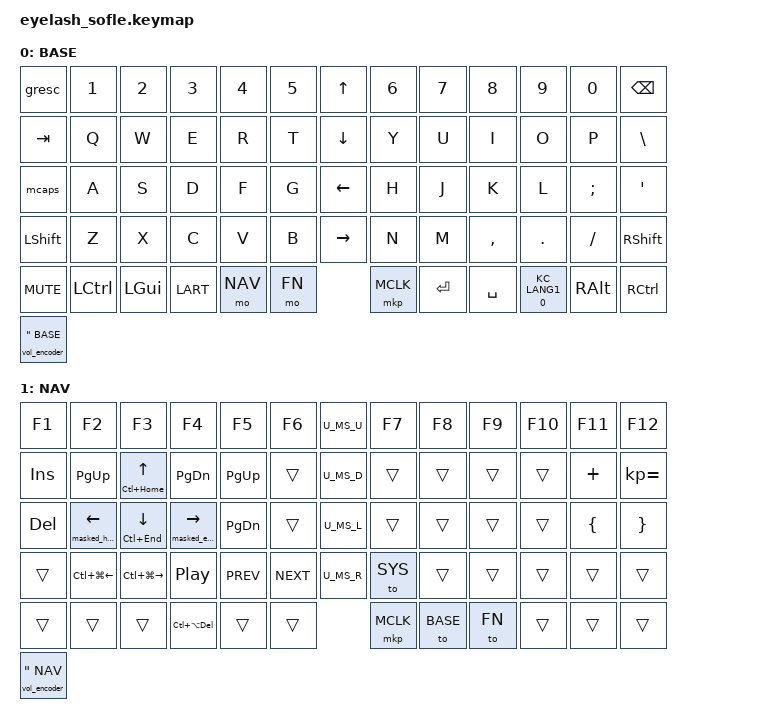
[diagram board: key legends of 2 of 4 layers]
/ {
#include <input/processors.dtsi>
#include <zephyr/dt-bindings/input/input-event-codes.h>
#include <behaviors.dtsi>
#include <dt-bindings/zmk/bt.h>
#include <dt-bindings/zmk/ext_power.h>
#include <dt-bindings/zmk/keys.h>
#include <dt-bindings/zmk/pointing.h>
#include <dt-bindings/zmk/outputs.h>
#include <dt-bindings/zmk/rgb.h>

#include "zmk-helpers/helper.h"
#include "zmk-helpers/key-labels/sofle_eyelash_3c.h"


/* ──────────────────────────────────────────────────────────────── */
/*                        Constants & Defaults                      */
/* ──────────────────────────────────────────────────────────────── */

#define COMBO_TERM_FAST 18
#define COMBO_TERM_SLOW 30

#define COMBO_IDLE_FAST 150
#define COMBO_IDLE_SLOW 50

#define XXX &none
#define ___ &trans

#define QUICK_TAP_MS 175

#define BASE 0
#define NAV 1
#define FN 2
#define SYS 3

#define DLEFT  &kp LC(LG(LEFT_ARROW))
#define DRIGHT &kp LC(LG(RIGHT_ARROW))
#define HYPER &kp LC(LA(LG(LSHFT)))

#define KEYS_L LT0 LT1 LT2 LT3 LT4 LM0 LM1 LM2 LM3 LM4 LB0 LB1 LB2 LB3 LB4  // Left-hand keys
#define KEYS_R RT0 RT1 RT2 RT3 RT4 RM0 RM1 RM2 RM3 RM4 RB0 RB1 RB2 RB3 RB4  // Right-hand keys
#define THUMBS LH4 LH3 LH2 LH1 LH0 RH0 RH1 RH2 RH3 RH4                      // Thumb keys

/* ──────────────────────────────────────────────────────────────── */
/*                     Home Row Mods (Timeless HRMs)                */
/* ──────────────────────────────────────────────────────────────── */

#define MAKE_HRM(NAME, HOLD, TAP, TRIGGER_POS)                                 \
  ZMK_HOLD_TAP(NAME, bindings = <HOLD>, <TAP>; flavor = "balanced";            \
               tapping-term-ms = <280>; quick-tap-ms = <QUICK_TAP_MS>;         \
               require-prior-idle-ms = <150>; hold-trigger-on-release;         \
               hold-trigger-key-positions = <TRIGGER_POS>;)

MAKE_HRM(hml, &kp, &kp, KEYS_R THUMBS) // Left-hand HRMs
MAKE_HRM(hmr, &kp, &kp, KEYS_L THUMBS) // Right-hand HRMs


/* ──────────────────────────────────────────────────────────────── */
/*                         Encoder behaviors                        */
/* ──────────────────────────────────────────────────────────────── */

/ {
  rgb_encoder: rgb_encoder {
      compatible = "zmk,behavior-sensor-rotate";
      #sensor-binding-cells = <0>;
      bindings = <&rgb_ug RGB_BRI>, <&rgb_ug RGB_BRD>;
      tap-ms = <20>;
  };

  vol_encoder: vol_encoder {
      compatible = "zmk,behavior-sensor-rotate";
      #sensor-binding-cells = <0>;
      bindings = <&kp C_VOL_UP>, <&kp C_VOL_DN>;
      tap-ms = <20>;
  };
};


/* ──────────────────────────────────────────────────────────────── */
/*                            Nav cluster                           */
/* ──────────────────────────────────────────────────────────────── */

#define MT_CORE                                                                \
  flavor = "tap-preferred";                                                    \
  tapping-term-ms = <220>;                                                     \
  quick-tap-ms = <220>;                                                        \
  hold-trigger-key-positions = <0>;

&mt { MT_CORE };

// Modifier-morphing wrapper to mask accidental cursor jumps
#define MASK_MODS(NAME, MODS, BINDING)                                         \
  ZMK_MOD_MORPH(NAME, bindings = <BINDING>, <BINDING>; mods = <MODS>;)

MASK_MODS(masked_home, (MOD_LCTL), &kp HOME)
MASK_MODS(masked_end,  (MOD_LCTL), &kp END)

ZMK_HOLD_TAP(mt_home, bindings = <&masked_home>, <&kp>; MT_CORE)
ZMK_HOLD_TAP(mt_end, bindings = <&masked_end>, <&kp>; MT_CORE)

// 새로운 ZMK_HOLD_TAP 비헤이비어 정의
// 짧게 누르면 한영 전환 (KC_LANG1), 길게 누르면 KC_APP
ZMK_HOLD_TAP(han_eng_app_ht,
  bindings = <&kp KC_APP>,    // 홀드 액션: KC_APP (어플리케이션/컨텍스트 메뉴 키)
             <&kp>;           // 탭 액션: &kp 매크로에 키 코드를 전달할 준비
  MT_CORE                     // MT_CORE에서 정의된 공통 탭/홀드 속성 사용
)

#define NAV_LEFT  &mt_home 0   LEFT  // Tap: left  | Long-tap: start of line.
#define NAV_RIGHT &mt_end 0    RIGHT // Tap: right | Long-tap: end   of line.
#define NAV_UP    &mt LC(HOME) UP    // Tap: up    | Long-tap: start of doc.
#define NAV_DOWN  &mt LC(END)  DOWN  // Tap: down  | Long-tap: end   of doc.

// 이제 키맵에 이 비헤이비어를 할당할 수 있는 매크로를 정의
// '#define' 문을 사용하여 키맵 레이어에 쉽게 사용할 수 있도록 합니다.
// (여기서는 KC_LANG1을 한영 전환 키로 사용합니다. 시스템에 따라 KC_RALT를 사용할 수도 있습니다.)
#define HAN_ENG_APP_KEY &han_eng_app_ht 0 KC_LANG1 // 짧게: 한영 전환 | 길게: KC_APP

// 만약 KC_RALT를 한영 전환 키로 선호한다면:
// #define HAN_ENG_APP_KEY_RALT &han_eng_app_ht 0 KC_RALT // 짧게: 한영 전환 (오른쪽 Alt) | 길게: KC_APP


/* ──────────────────────────────────────────────────────────────── */
/*                              Combos                              */
/* ──────────────────────────────────────────────────────────────── */

ZMK_COMBO(selectall, &kp LC(A), LB4 LB3, BASE, COMBO_TERM_FAST, COMBO_IDLE_FAST)
ZMK_COMBO(copy,      &kp LC(C), LB3 LB2, BASE, COMBO_TERM_FAST, COMBO_IDLE_FAST)
ZMK_COMBO(paste,     &kp LC(V), LB2 LB1, BASE, COMBO_TERM_FAST, COMBO_IDLE_FAST)

ZMK_COMBO(lbkt, &kp LBKT, RB1 RB2, BASE, COMBO_TERM_FAST, COMBO_IDLE_FAST)
ZMK_COMBO(rbkt, &kp RBKT, RB2 RB3, BASE, COMBO_TERM_FAST, COMBO_IDLE_FAST)

// 새로운 콤보: Layer 1 키와 Layer 2 키를 함께 눌러 Layer 3으로 이동
ZMK_COMBO(layer1_2_to_layer3,
          &to SYS, // 콤보 성공 시 SYS로 즉시 이동
          <LH1 LH0>, // 여기에 실제 "레이어 1 키"와 "레이어 2 키"의 위치(인덱스)를 입력
                           // 예: <10 15> (만약 P1_POS가 10, P2_POS가 15라면)
                           // 또는, 만약 LB1, LB2 등과 같은 매크로로 정의되어 있다면:
                           // <LB_LAYER1_KEY LB_LAYER2_KEY>
          BASE, // BASE 레이어에서 이 콤보가 작동하도록 허용 (필요에 따라 다른 레이어 추가 가능)
          COMBO_TERM_FAST, // 빠르게 눌렀다 떼야 작동
          COMBO_IDLE_FAST  // 콤보 키를 누른 상태에서 다른 키를 누르면 콤보 취소될 수 있음
)

/* ──────────────────────────────────────────────────────────────── */
/*                            Behaviors                             */
/* ──────────────────────────────────────────────────────────────── */

ZMK_BEHAVIOR(mcaps, macro,
  tap-ms = <200>;
  bindings = <&kp CAPS>;
)


/* ──────────────────────────────────────────────────────────────── */
/*                           Mouse bindings                         */
/* ──────────────────────────────────────────────────────────────── */

#include "mouse.dtsi"


/*                             63 KEY MATRIX / LAYOUT MAPPING
Based on the pre-built Sofle split keyboards from AliExpress, seller 3C, Nice!View edition
https://github.com/a741725193/zmk-sofle

  ╭────────────────────────────╮                             ╭────────────────────────────╮
  │  0   1   2   3   4   5     │               ╭────╮        │      7   8   9  10  11  12 │
  │ 13  14  15  16  17  18     │           ╭───╯  6 ╰───╮    │     20  21  22  23  24  25 │
  │ 26  27  28  29  30  31     │  ╭────╮   │ 32  58  45 │    │     33  34  35  36  37  38 │
  │ 39  40  41  42  43  44     │  │ 52 │   ╰───╮ 19 ╭───╯    │     46  47  48  49  50  51 │
  ╰───────╮ 53  54  55  56  57 │  ╰────╯       ╰────╯        │ 59  60  61  62  63 ╭───────╯
          ╰────────────────────╯                             ╰────────────────────╯
  ╭─────────────────────────────╮                            ╭─────────────────────────────╮          
  │ LN5 LN4 LN3 LN2 LN1 LN0     │              ╭─────╮       │     RN0 RN1 RN2 RN3 RN4 RN5 │
  │ LT5 LT4 LT3 LT2 LT1 LT0     │          ╭───╯ JS0 ╰───╮   │     RT0 RT1 RT2 RT3 RT4 RT5 │
  │ LM5 LM4 LM3 LM2 LM1 LM0     │ ╭─────╮  │ JS1 JS2 JS3 │   │     RM0 RM1 RM2 RM3 RM4 RM5 │
  │ LB5 LB4 LB3 LB2 LB1 LB0     │ │ LEC │  ╰───╮ JS4 ╭───╯   │     RB0 RB1 RB2 RB3 RB4 RB5 │
  ╰───────╮ LH4 LH3 LH2 LH1 LH0 │ ╰─────╯      ╰─────╯       │ RH0 RH1 RH2 RH3 RH4 ╭───────╯
          ╰─────────────────────╯                            ╰─────────────────────╯         */

ZMK_LAYER(BASE,
  //                                                                                                             HAT CONTROLS
  // ╭─────────────┬─────────────┬─────────────┬─────────────┬─────────────┬─────────────╮                      ╭─────────────────╮  ╭─────────────┬─────────────┬─────────────┬─────────────┬─────────────┬─────────────╮
      &gresc        &kp N1        &kp N2        &kp N3        &kp N4        &kp N5                                &kp UP_ARROW        &kp N6        &kp N7        &kp N8        &kp N9        &kp N0        &kp BACKSPACE 
  // ├─────────────┼─────────────┼─────────────┼─────────────┼─────────────┼─────────────┤                      ├─────────────────┤  ├─────────────┼─────────────┼─────────────┼─────────────┼─────────────┼─────────────┤
      &kp TAB       &kp Q         &kp W         &kp E         &kp R         &kp T                                 &kp DOWN_ARROW      &kp Y         &kp U         &kp I         &kp O         &kp P         &kp BACKSLASH        
  // ├─────────────┼─────────────┼─────────────┼─────────────┼─────────────┼─────────────┤                      ├─────────────────┤  ├─────────────┼─────────────┼─────────────┼─────────────┼─────────────┼─────────────┤
      &mcaps        &kp A         &kp S         &kp D         &kp F         &kp G                                 &kp LEFT_ARROW      &kp H         &kp J         &kp K         &kp L         &kp SEMI      &kp APOS        
  // ├─────────────┼─────────────┼─────────────┼─────────────┼─────────────┼─────────────┤                      ├─────────────────┤  ├─────────────┼─────────────┼─────────────┼─────────────┼─────────────┼─────────────┤
      &kp LSHIFT    &kp Z         &kp X         &kp C         &kp V         &kp B                                 &kp RIGHT_ARROW     &kp N         &kp M         &kp COMMA     &kp PERIOD    &kp SLASH     &kp RSHIFT
  // ╰┬──────────┬─┴─────────────┼─────────────┼─────────────┼─────────────┼─────────────┼─────────────╮   ╭────┴─────╮╭──────────┴──┴─────────────┼─────────────┼─────────────┼─────────────┼─────────────┼─────────────┼
       &kp C_MUTE                 &kp LCTRL     &kp LGUI      &kp LART     &mo NAV       &mo FN            &mkp MCLK   &kp ENTER     &kp SPACE     HAN_ENG_APP_KEY &kp RALT     &kp RCTRL
  //  ╰──────────╯               ╰─────────────┴─────────────┴─────────────┴─────────────┴─────────────╯   ╰──────────╯╰─────────────┴─────────────┴─────────────┴─────────────┴─────────────╯
  //  ENCODER PRESS                                                                                         HAT PRESS
, &vol_encoder, "BASE")

ZMK_LAYER(NAV,
  //                                                                                                             HAT CONTROLS
  // ╭─────────────┬─────────────┬─────────────┬─────────────┬─────────────┬─────────────╮                      ╭─────────────────╮  ╭─────────────┬─────────────┬─────────────┬─────────────┬─────────────┬─────────────╮
      &kp F1        &kp F2        &kp F3        &kp F4        &kp F5        &kp F6                               U_MS_U               &kp F7        &kp F8        &kp F9        &kp F10       &kp F11       &kp F12 
  // ├─────────────┼─────────────┼─────────────┼─────────────┼─────────────┼─────────────┤                      ├─────────────────┤  ├─────────────┼─────────────┼─────────────┼─────────────┼─────────────┼─────────────┤
      &kp INSERT    &kp PG_UP     NAV_UP        &kp PG_DN     &kp PG_UP     ___                                  U_MS_D               ___           ___           ___           ___           &kp PLUS      &kp KP_EQUAL        
  // ├─────────────┼─────────────┼─────────────┼─────────────┼─────────────┼─────────────┤                      ├─────────────────┤  ├─────────────┼─────────────┼─────────────┼─────────────┼─────────────┼─────────────┤
      &kp DEL       NAV_LEFT      NAV_DOWN      NAV_RIGHT     &kp PG_DN     ___                                  U_MS_L               ___           ___           ___           ___           &kp LBRC      &kp RBRC         
  // ├─────────────┼─────────────┼─────────────┼─────────────┼─────────────┼─────────────┤                      ├─────────────────┤  ├─────────────┼─────────────┼─────────────┼─────────────┼─────────────┼─────────────┤
      ___           DLEFT         DRIGHT        &kp C_PP      &kp C_PREV    &kp C_NEXT                           U_MS_R               &to SYS       ___           ___           ___           ___           ___ 
  // ╰┬──────────┬─┴─────────────┼─────────────┼─────────────┼─────────────┼─────────────┼─────────────╮   ╭────┴─────╮╭──────────┴──┴─────────────┼─────────────┼─────────────┼─────────────┼─────────────┼─────────────┼
       ___                        ___           ___           &kp LC(LA(DEL)) ___         ___               &mkp MCLK   &to BASE      &to FN        ___           ___           ___
  //  ╰──────────╯               ╰─────────────┴─────────────┴─────────────┴─────────────┴─────────────╯   ╰──────────╯╰─────────────┴─────────────┴─────────────┴─────────────┴─────────────╯
  //  ENCODER PRESS                                                                                         HAT PRESS
, &vol_encoder, "NAV")

ZMK_LAYER(FN,
  //                                                                                                             HAT CONTROLS
  // ╭─────────────┬─────────────┬─────────────┬─────────────┬─────────────┬─────────────╮                      ╭─────────────────╮  ╭─────────────┬─────────────┬─────────────┬─────────────┬─────────────┬─────────────╮
      ___           &kp F1        &kp F2        &kp F3        &kp F4        &kp F5                               U_MS_U               ___           &kp NUM       &kp PSLS      &kp PASTE     &kp PMNS      ___ 
  // ├─────────────┼─────────────┼─────────────┼─────────────┼─────────────┼─────────────┤                      ├─────────────────┤  ├─────────────┼─────────────┼─────────────┼─────────────┼─────────────┼─────────────┤
      ___           &kp PG_UP     NAV_UP        &kp PG_DN     &kp PG_UP     ___                                  U_MS_D               ___           &kp P7        &kp P8        &kp P9        &kp PPLS        
  // ├─────────────┼─────────────┼─────────────┼─────────────┼─────────────┼─────────────┤                      ├─────────────────┤  ├─────────────┼─────────────┼─────────────┼─────────────┼─────────────┼─────────────┤
      ___           NAV_LEFT      NAV_DOWN      NAV_RIGHT     &kp PG_DN     ___                                  U_MS_L               ___           &kp P4        &kp P5        &kp P6        ___           ___         
  // ├─────────────┼─────────────┼─────────────┼─────────────┼─────────────┼─────────────┤                      ├─────────────────┤  ├─────────────┼─────────────┼─────────────┼─────────────┼─────────────┼─────────────┤
      ___           ___           ___           ___           ___           ___                                  U_MS_R               &to SYS       &kp P1        &kp P2        &kp P3        &kp PENT      ___ 
  // ╰┬──────────┬─┴─────────────┼─────────────┼─────────────┼─────────────┼─────────────┼─────────────╮   ╭────┴─────╮╭──────────┴──┴─────────────┼─────────────┼─────────────┼─────────────┼─────────────┼─────────────┼
       ___                        ___           ___           ___           ___           ___               &mkp MCLK   &to BASE      &to NAV       &kp P0        &kp P0        &kp PDOT
  //  ╰──────────╯               ╰─────────────┴─────────────┴─────────────┴─────────────┴─────────────╯   ╰──────────╯╰─────────────┴─────────────┴─────────────┴─────────────┴─────────────╯
  //  ENCODER PRESS                                                                                         HAT PRESS
, &vol_encoder, "FN")

ZMK_LAYER(SYS,
  //                                                                                                             HAT CONTROLS
  // ╭─────────────┬─────────────┬─────────────┬─────────────┬─────────────┬─────────────╮                      ╭─────────────────╮  ╭─────────────┬─────────────┬─────────────┬─────────────┬─────────────┬─────────────╮
      ___           &bt BT_SEL 0  &bt BT_SEL 1  &bt BT_SEL 2  &bt BT_SEL 3  &bt BT_SEL 4                         &rgb_ug RGB_HUI      ___           ___           ___           ___           ___           ___ 
  // ├─────────────┼─────────────┼─────────────┼─────────────┼─────────────┼─────────────┤                      ├─────────────────┤  ├─────────────┼─────────────┼─────────────┼─────────────┼─────────────┼─────────────┤
      ___           ___           ___           ___           ___           ___                                  &rgb_ug RGB_HUD      ___           &out OUT_USB  ___           ___           ___           ___        
  // ├─────────────┼─────────────┼─────────────┼─────────────┼─────────────┼─────────────┤                      ├─────────────────┤  ├─────────────┼─────────────┼─────────────┼─────────────┼─────────────┼─────────────┤
      ___           ___           ___           ___           ___           ___                                  &rgb_ug RGB_SAD      &rgb_ug RGB_EFI &rgb_ug RGB_SPI           ___           ___           ___           
  // ├─────────────┼─────────────┼─────────────┼─────────────┼─────────────┼─────────────┤                      ├─────────────────┤  ├─────────────┼─────────────┼─────────────┼─────────────┼─────────────┼─────────────┤
      ___           ___           ___           &bt BT_CLR    ___           &out OUT_BLE                         &rgb_ug RGB_SAI      &rgb_ug RGB_EFD &rgb_ug RGB_SPD           ___           ___           ___            
  // ╰┬──────────┬─┴─────────────┼─────────────┼─────────────┼─────────────┼─────────────┼─────────────╮   ╭────┴─────╮╭──────────┴──┴─────────────┼─────────────┼─────────────┼─────────────┼─────────────┼─────────────┼
       &rgb_ug RGB_TOG            ___           ___           ___           ___           ___               &mkp LCLK   &to BASE      &to NAV       ___           ___           ___
  //  ╰──────────╯               ╰─────────────┴─────────────┴─────────────┴─────────────┴─────────────╯   ╰──────────╯╰─────────────┴─────────────┴─────────────┴─────────────┴─────────────╯
  //  ENCODER PRESS                                                                                         HAT PRESS
, &rgb_encoder, "SYS")
};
